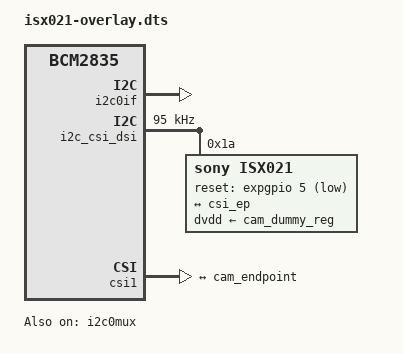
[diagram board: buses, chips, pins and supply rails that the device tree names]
// SPDX-License-Identifier: GPL-2.0-only
// Definitions for ISX021 camera module on VC I2C bus
/dts-v1/;
/plugin/;

#include <dt-bindings/gpio/gpio.h>

/{
	compatible = "brcm,bcm2835";

	fragment@8 {
		target = <&i2c0if>;
		__overlay__ {
			status = "okay";
		};
	};

	clk_frag: fragment@1 {
		target = <&cam1_clk>;
		__overlay__ {
			status = "okay";
			clock-frequency = <24000000>;
		};
	};

	fragment@3 {
		target = <&i2c0mux>;
		__overlay__ {
			status = "okay";
		};
	};

	i2c_frag: fragment@100 {
		target = <&i2c_csi_dsi>;
		__overlay__ {
			#address-cells = <1>;
			#size-cells = <0>;
			status = "okay";
			clock-frequency = <95000>;
				isx021: isx021@1a {
					compatible = "sony,isx021";
					reg = <0x1a>;
					#address-cells = <1>;
					#size-cells = <0>;
					clocks = <&cam1_clk>;
					clock-names = "xclk";
					dvdd-supply = <&cam_dummy_reg>;
					reset-gpios = <&expgpio 5 GPIO_ACTIVE_LOW>;

					port {
						cam_endpoint: endpoint {
							remote-endpoint = <&csi1_ep>;
							clock-lanes = <0>;
							data-lanes = <1 2>;
						};
					};
				};
		};
	};

	csi_frag: fragment@101 {
		target = <&csi1>;
		csi: __overlay__ {
			status = "okay";
			brcm,media-controller;

			port {
				csi_ep: endpoint {
					remote-endpoint = <&cam_endpoint>;
					clock-lanes = <0>;
					data-lanes = <1 2>;
				};
			};
		};
	};
	fragment@2 {
		target = <&cam1_reg>;
		__overlay__ {
			regulator-always-on;
			status = "disabled";
		};
	};		

	__overrides__ {
		media-controller = <&csi>,"brcm,media-controller?";
		cam0 = <&i2c_frag>, "target:0=",<&i2c_vc>,
		       <&csi_frag>, "target:0=",<&csi0>;
	};

};

&cam_endpoint {
	remote-endpoint = <&csi_ep>;
};
